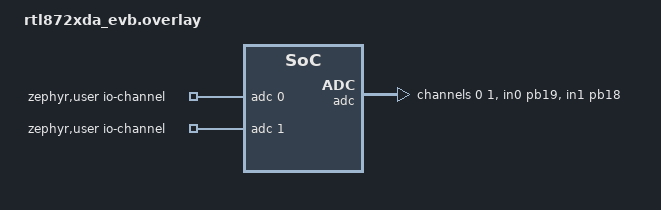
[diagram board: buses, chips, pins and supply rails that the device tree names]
/*
 * Copyright (c) 2024 Realtek Semiconductor Corp.
 *
 * SPDX-License-Identifier: Apache-2.0
 */

/ {
	zephyr,user {
		io-channels = <&adc 0>, <&adc 1>;
	};
};

&adc {
	pinctrl-0 = <&adc_in0_pb19 &adc_in1_pb18>;
	#address-cells = <1>;
	#size-cells = <0>;

	channel@0 {
		reg = <0>;
		zephyr,gain = "ADC_GAIN_1";
		zephyr,reference = "ADC_REF_INTERNAL";
		zephyr,acquisition-time = <ADC_ACQ_TIME_MAX>;
		zephyr,resolution = <12>;
	};

	channel@1 {
		reg = <1>;
		zephyr,gain = "ADC_GAIN_1";
		zephyr,reference = "ADC_REF_INTERNAL";
		zephyr,acquisition-time = <ADC_ACQ_TIME_MAX>;
		zephyr,resolution = <12>;
	};
};
